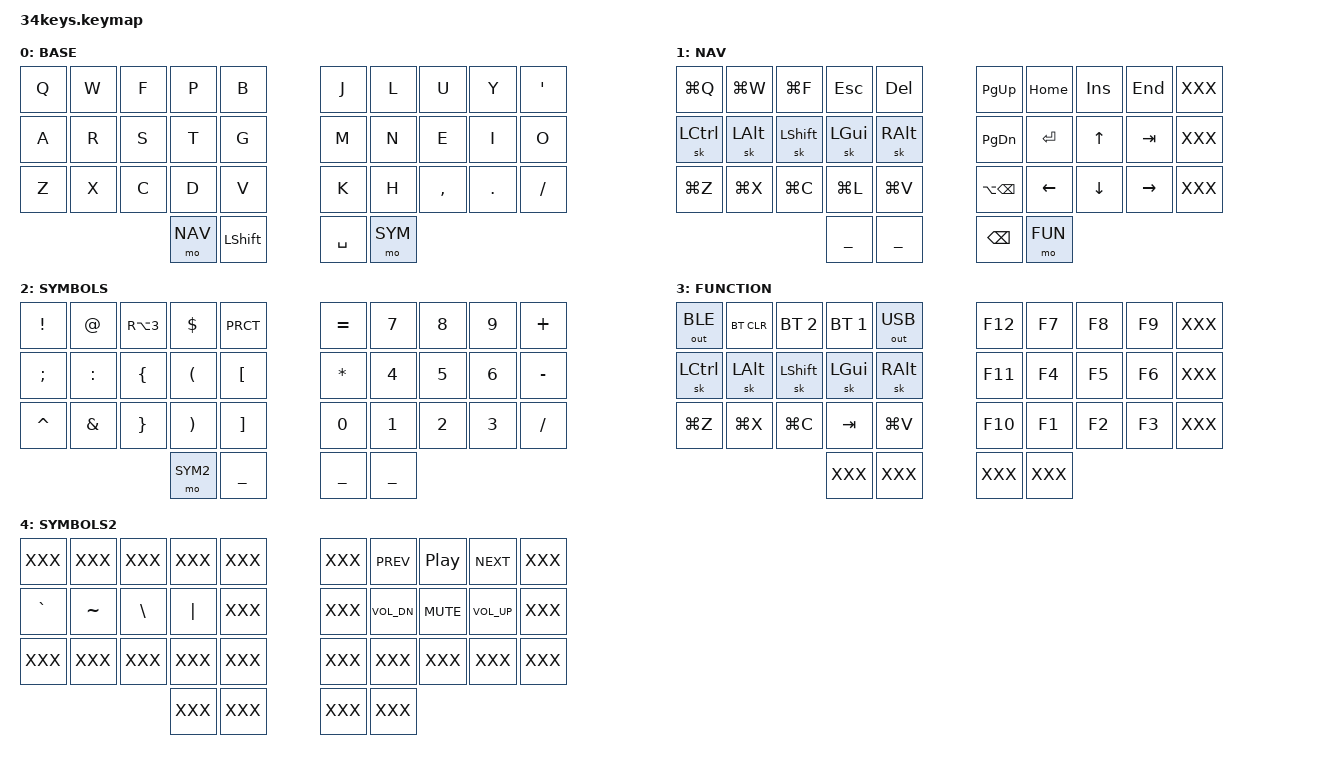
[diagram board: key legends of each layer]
#include <behaviors.dtsi>
#include <dt-bindings/zmk/keys.h>
#include <dt-bindings/zmk/bt.h>
#include <dt-bindings/zmk/outputs.h>
#include "oled.dtsi"
#include "34keys.h"

/ {

  keymap {
    compatible = "zmk,keymap";

    base_layer {
      label = "BASE";
      bindings = <
        // ╭─────────────┬─────────────┬─────────────┬─────────────┬─────────────╮   ╭─────────────┬─────────────┬─────────────┬─────────────┬─────────────╮
             &kp Q         &kp W         &kp F         &kp P         &kp B             &kp J         &kp L         &kp U         &kp Y         &kp SQT
        // ├─────────────┼─────────────┼─────────────┼─────────────┼─────────────┤   ├─────────────┼─────────────┼─────────────┼─────────────┼─────────────┤
             &kp A         &kp R         &kp S         &kp T         &kp G             &kp M         &kp N         &kp E         &kp I         &kp O
        // ├─────────────┼─────────────┼─────────────┼─────────────┼─────────────┤   ├─────────────┼─────────────┼─────────────┼─────────────┼─────────────┤
             &kp Z         &kp X         &kp C         &kp D         &kp V             &kp K         &kp H         &kp COMMA     &kp DOT       &kp SLASH
        // ╰─────────────┴─────────────┴─────────────┼─────────────┼─────────────┤   ├─────────────┼─────────────┼─────────────┴─────────────┴─────────────╯
                                                       &mo NAV       &kp LSHIFT        &kp SPC       &mo SYM
        //                                           ╰─────────────┴─────────────╯   ╰─────────────┴─────────────╯
      >;
    };

    nav_layer {
      label = "NAV";
      bindings = <
        // ╭─────────────┬─────────────┬─────────────┬─────────────┬─────────────╮   ╭─────────────┬─────────────┬─────────────┬─────────────┬─────────────╮
             &kp LG(Q)     &kp LG(W)     &kp LG(F)     &kp ESC       &kp DEL           &kp PG_UP     &kp HOME      &kp INS       &kp END       XXX
        // ├─────────────┼─────────────┼─────────────┼─────────────┼─────────────┤   ├─────────────┼─────────────┼─────────────┼─────────────┼─────────────┤
             &sk LCTRL     &sk LALT      &sk LSHIFT    &sk LGUI      &sk RALT          &kp PG_DN     &kp ENTER     &kp UP        &kp TAB       XXX
        // ├─────────────┼─────────────┼─────────────┼─────────────┼─────────────┤   ├─────────────┼─────────────┼─────────────┼─────────────┼─────────────┤
             &kp LG(Z)     &kp LG(X)     &kp LG(C)     &kp LG(L)     &kp LG(V)         &kp LA(BSPC)  &kp LEFT      &kp DOWN      &kp RIGHT     XXX
        // ╰─────────────┴─────────────┴─────────────┼─────────────┼─────────────┤   ├─────────────┼─────────────┼─────────────┴─────────────┴─────────────╯
                                                       ___           ___               &kp BSPC      &mo FUN
        //                                           ╰─────────────┴─────────────╯   ╰─────────────┴─────────────╯
      >;
    };

    sym_layer {
      label = "SYMBOLS";
      bindings = <
        // ╭─────────────┬─────────────┬─────────────┬─────────────┬─────────────╮   ╭─────────────┬─────────────┬─────────────┬─────────────┬─────────────╮
             &kp EXCL      &kp AT        &kp RA(N3)    &kp DLLR      &kp PRCT          &kp EQUAL     &kp N7        &kp N8        &kp N9        &kp PLUS
        // ├─────────────┼─────────────┼─────────────┼─────────────┼─────────────┤   ├─────────────┼─────────────┼─────────────┼─────────────┼─────────────┤
             &kp SEMI      &kp COLON     &kp LBRC      &kp LPRN      &kp LBKT          &kp STAR      &kp N4        &kp N5        &kp N6        &kp MINUS
        // ├─────────────┼─────────────┼─────────────┼─────────────┼─────────────┤   ├─────────────┼─────────────┼─────────────┼─────────────┼─────────────┤
             &kp CARET     &kp AMPS      &kp RBRC      &kp RPRN      &kp RBKT          &kp N0        &kp N1        &kp N2        &kp N3        &kp FSLH
        // ╰─────────────┴─────────────┴─────────────┼─────────────┼─────────────┤   ├─────────────┼─────────────┼─────────────┴─────────────┴─────────────╯
                                                       &mo SYM2      ___               ___           ___
        //                                           ╰─────────────┴─────────────╯   ╰─────────────┴─────────────╯
      >;
    };

    function_layer {
      label = "FUNCTION";
      bindings = <
        // ╭─────────────┬─────────────┬─────────────┬─────────────┬─────────────╮   ╭─────────────┬─────────────┬─────────────┬─────────────┬─────────────╮
             &out OUT_BLE  &bt BT_CLR    &bt BT_SEL 2  &bt BT_SEL 1  &out OUT_USB      &kp F12       &kp F7        &kp F8        &kp F9        XXX
        // ├─────────────┼─────────────┼─────────────┼─────────────┼─────────────┤   ├─────────────┼─────────────┼─────────────┼─────────────┼─────────────┤
             &sk LCTRL     &sk LALT      &sk LSHIFT    &sk LGUI      &sk RALT          &kp F11       &kp F4        &kp F5        &kp F6        XXX 
        // ├─────────────┼─────────────┼─────────────┼─────────────┼─────────────┤   ├─────────────┼─────────────┼─────────────┼─────────────┼─────────────┤
             &kp LG(Z)     &kp LG(X)     &kp LG(C)     &kp TAB       &kp LG(V)         &kp F10       &kp F1        &kp F2        &kp F3        XXX
        // ╰─────────────┴─────────────┴─────────────┼─────────────┼─────────────┤   ├─────────────┼─────────────┼─────────────┴─────────────┴─────────────╯
                                                       XXX           XXX               XXX           XXX 
        //                                           ╰─────────────┴─────────────╯   ╰─────────────┴─────────────╯
      >;
    };

    sym2_layer {
      label = "SYMBOLS2";
      bindings = <
        // ╭─────────────┬─────────────┬─────────────┬─────────────┬─────────────╮   ╭─────────────┬─────────────┬─────────────┬─────────────┬─────────────╮
             XXX           XXX           XXX           XXX           XXX               XXX           &kp C_PREV    &kp C_PP      &kp C_NEXT    XXX
        // ├─────────────┼─────────────┼─────────────┼─────────────┼─────────────┤   ├─────────────┼─────────────┼─────────────┼─────────────┼─────────────┤
             &kp GRAVE     &kp TILDE     &kp BSLH      &kp PIPE      XXX               XXX           &kp C_VOL_DN  &kp K_MUTE    &kp C_VOL_UP  XXX 
        // ├─────────────┼─────────────┼─────────────┼─────────────┼─────────────┤   ├─────────────┼─────────────┼─────────────┼─────────────┼─────────────┤
             XXX           XXX           XXX           XXX           XXX               XXX           XXX           XXX           XXX           XXX
        // ╰─────────────┴─────────────┴─────────────┼─────────────┼─────────────┤   ├─────────────┼─────────────┼─────────────┴─────────────┴─────────────╯
                                                       XXX           XXX               XXX           XXX
        //                                           ╰─────────────┴─────────────╯   ╰─────────────┴─────────────╯
      >;
    };

  };
};
